VERSION ""

NS_ :

BS_:

BU_: ECU Display VCU SteeringWheel WirelessGateway DATA_COLLECTION_INTEGRAL VEHICLE_LOGGER PDM FanController BMS_Master Competition_Meter FS_Datalogger Chroma LegacyCharger

BO_ 1289 Debug9: 5 ECU
 SG_ LogicState_RR : 24|4@1+ (1,0) [0|15] "" Vector__XXX
 SG_ LogicState_RL : 28|4@1+ (1,0) [0|15] "" Vector__XXX
 SG_ LogicState_FR : 32|4@1+ (1,0) [0|15] "" Vector__XXX
 SG_ LogicState_FL : 36|4@1+ (1,0) [0|15] "" Vector__XXX
 SG_ FR_AMK_bEnable : 20|1@1+ (1,0) [0|1] "" Vector__XXX
 SG_ FL_AMK_bEnable : 21|1@1+ (1,0) [0|1] "" Vector__XXX
 SG_ RR_AMK_bEnable : 22|1@1+ (1,0) [0|1] "" Vector__XXX
 SG_ RL_AMK_bEnable : 23|1@1+ (1,0) [0|1] "" Vector__XXX
 SG_ FR_AMK_bQuitInverterOn : 16|1@1+ (1,0) [0|1] "" Vector__XXX
 SG_ FL_AMK_bQuitInverterOn : 17|1@1+ (1,0) [0|1] "" Vector__XXX
 SG_ RR_AMK_bQuitInverterOn : 18|1@1+ (1,0) [0|1] "" Vector__XXX
 SG_ RL_AMK_bQuitInverterOn : 19|1@1+ (1,0) [0|1] "" Vector__XXX
 SG_ FR_AMK_bQuitDcOn : 12|1@1+ (1,0) [0|1] "" Vector__XXX
 SG_ FL_AMK_bQuitDcOn : 13|1@1+ (1,0) [0|1] "" Vector__XXX
 SG_ RR_AMK_bQuitDcOn : 14|1@1+ (1,0) [0|1] "" Vector__XXX
 SG_ RL_AMK_bQuitDcOn : 15|1@1+ (1,0) [0|1] "" Vector__XXX
 SG_ FR_AMK_bSystemReady : 8|1@1+ (1,0) [0|1] "" Vector__XXX
 SG_ FL_AMK_bSystemReady : 9|1@1+ (1,0) [0|1] "" Vector__XXX
 SG_ RR_AMK_bSystemReady : 10|1@1+ (1,0) [0|1] "" Vector__XXX
 SG_ RL_AMK_bSystemReady : 11|1@1+ (1,0) [0|1] "" Vector__XXX
 SG_ FR_AMK_bError : 0|1@1+ (1,0) [0|1] "" Vector__XXX
 SG_ FL_AMK_bError : 1|1@1+ (1,0) [0|1] "" Vector__XXX
 SG_ RR_AMK_bError : 2|1@1+ (1,0) [0|1] "" Vector__XXX
 SG_ RL_AMK_bError : 3|1@1+ (1,0) [0|1] "" Vector__XXX
 SG_ ModeFlag : 4|4@1- (1,0) [-8|7] "" Vector__XXX

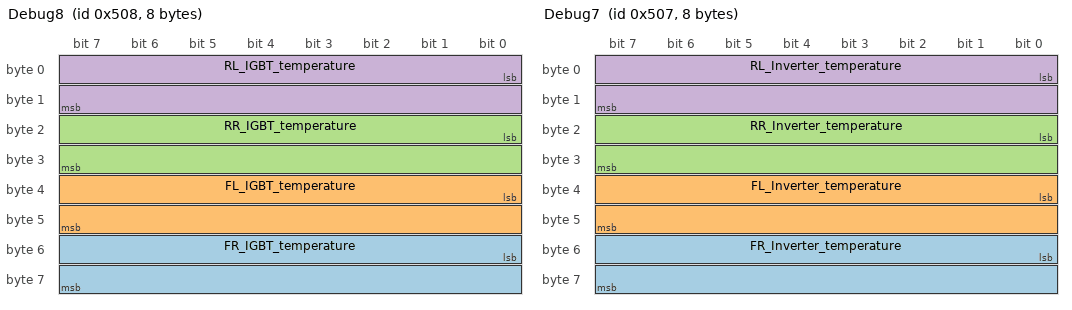
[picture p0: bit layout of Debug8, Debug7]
BO_ 1288 Debug8: 8 ECU
 SG_ FR_IGBT_temperature : 48|16@1- (0.1,0) [-3276.8|3276.7] "degC" Vector__XXX
 SG_ FL_IGBT_temperature : 32|16@1- (0.1,0) [-3276.8|3276.7] "degC" Vector__XXX
 SG_ RR_IGBT_temperature : 16|16@1- (0.1,0) [-3276.8|3276.7] "degC" Vector__XXX
 SG_ RL_IGBT_temperature : 0|16@1- (0.1,0) [-3276.8|3276.7] "degC" Vector__XXX

BO_ 1287 Debug7: 8 ECU
 SG_ FR_Inverter_temperature : 48|16@1- (0.1,0) [-3276.8|3276.7] "degC" Vector__XXX
 SG_ FL_Inverter_temperature : 32|16@1- (0.1,0) [-3276.8|3276.7] "degC" Vector__XXX
 SG_ RR_Inverter_temperature : 16|16@1- (0.1,0) [-3276.8|3276.7] "degC" Vector__XXX
 SG_ RL_Inverter_temperature : 0|16@1- (0.1,0) [-3276.8|3276.7] "degC" Vector__XXX

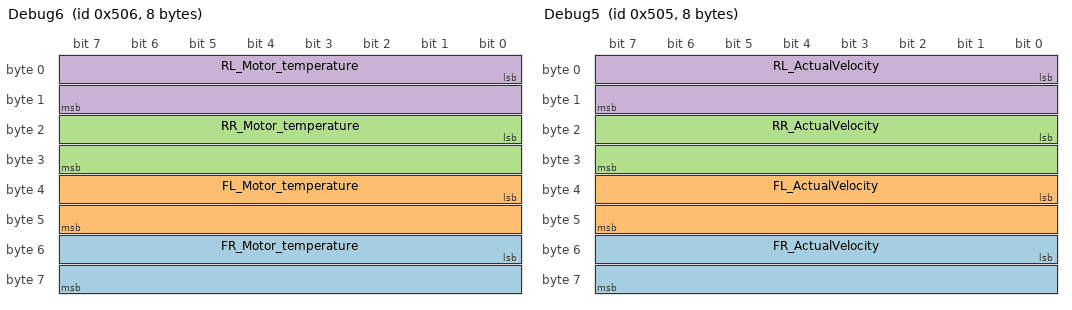
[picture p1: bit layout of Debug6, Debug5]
BO_ 1286 Debug6: 8 ECU
 SG_ FR_Motor_temperature : 48|16@1- (0.1,0) [-3276.8|3276.7] "degC" Vector__XXX
 SG_ FL_Motor_temperature : 32|16@1- (0.1,0) [-3276.8|3276.7] "degC" Vector__XXX
 SG_ RR_Motor_temperature : 16|16@1- (0.1,0) [-3276.8|3276.7] "degC" Vector__XXX
 SG_ RL_Motor_temperature : 0|16@1- (0.1,0) [-3276.8|3276.7] "degC" Vector__XXX

BO_ 1285 Debug5: 8 ECU
 SG_ FR_ActualVelocity : 48|16@1- (1,0) [-32768|32767] "" Vector__XXX
 SG_ FL_ActualVelocity : 32|16@1- (1,0) [-32768|32767] "" Vector__XXX
 SG_ RR_ActualVelocity : 16|16@1- (1,0) [-32768|32767] "" Vector__XXX
 SG_ RL_ActualVelocity : 0|16@1- (1,0) [-32768|32767] "" Vector__XXX

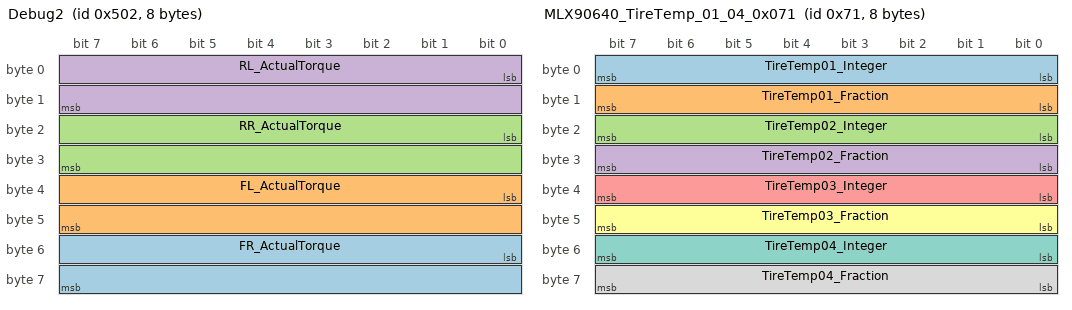
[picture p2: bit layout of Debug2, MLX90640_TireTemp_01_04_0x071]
BO_ 1282 Debug2: 8 ECU
 SG_ FR_ActualTorque : 48|16@1- (1,0) [-32768|32767] "0.1%Mn" Vector__XXX
 SG_ FL_ActualTorque : 32|16@1- (1,0) [-32768|32767] "0.1%Mn" Vector__XXX
 SG_ RR_ActualTorque : 16|16@1- (1,0) [-32768|32767] "0.1%Mn" Vector__XXX
 SG_ RL_ActualTorque : 0|16@1- (1,0) [-32768|32767] "0.1%Mn" Vector__XXX

BO_ 773 DataLogger: 6 ECU
 SG_ OilPressure_Kpa : 32|16@1+ (0.001,0) [0|65.535] "Kpa" Vector__XXX
 SG_ APS_OpenPct : 16|16@1+ (0.1,0) [0|6553.5] "%" Vector__XXX
 SG_ SteeringWheelAngle : 0|16@1- (0.1,0) [-3276.8|3276.7] "deg" Vector__XXX

BO_ 1284 Debug4: 8 ECU
 SG_ Diagnostic_number_4 : 32|32@1+ (1,0) [0|4294967295] "" Vector__XXX
 SG_ Diagnostic_number_3 : 0|32@1+ (1,0) [0|4294967295] "" Vector__XXX

BO_ 1283 Debug3: 8 ECU
 SG_ Diagnostic_number_2 : 32|32@1+ (1,0) [0|4294967295] "" Vector__XXX
 SG_ Diagnostic_number_1 : 0|32@1+ (1,0) [0|4294967295] "" Vector__XXX

BO_ 113 MLX90640_TireTemp_01_04_0x071: 8 DATA_COLLECTION_INTEGRAL
 SG_ TireTemp01_Integer : 0|8@1+ (1,0) [0|255] "degC"  Display,WirelessGateway,VEHICLE_LOGGER
 SG_ TireTemp01_Fraction : 8|8@1+ (0.01,0) [0|0.99] "degC"  Display,WirelessGateway,VEHICLE_LOGGER
 SG_ TireTemp02_Integer : 16|8@1+ (1,0) [0|255] "degC"  Display,WirelessGateway,VEHICLE_LOGGER
 SG_ TireTemp02_Fraction : 24|8@1+ (0.01,0) [0|0.99] "degC"  Display,WirelessGateway,VEHICLE_LOGGER
 SG_ TireTemp03_Integer : 32|8@1+ (1,0) [0|255] "degC"  Display,WirelessGateway,VEHICLE_LOGGER
 SG_ TireTemp03_Fraction : 40|8@1+ (0.01,0) [0|0.99] "degC"  Display,WirelessGateway,VEHICLE_LOGGER
 SG_ TireTemp04_Integer : 48|8@1+ (1,0) [0|255] "degC"  Display,WirelessGateway,VEHICLE_LOGGER
 SG_ TireTemp04_Fraction : 56|8@1+ (0.01,0) [0|0.99] "degC"  Display,WirelessGateway,VEHICLE_LOGGER

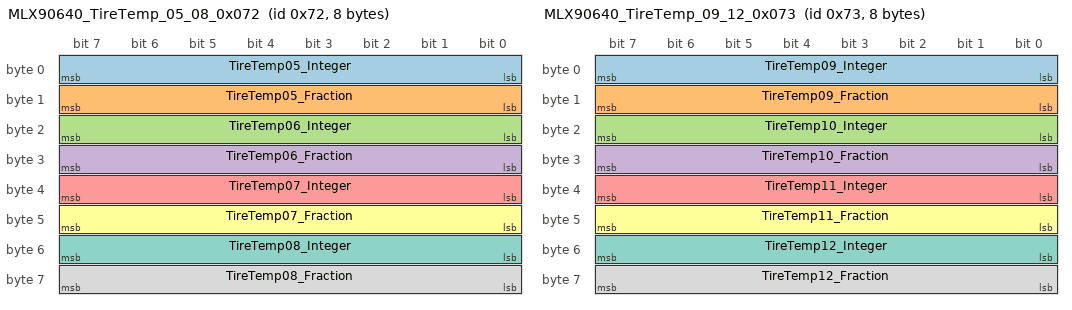
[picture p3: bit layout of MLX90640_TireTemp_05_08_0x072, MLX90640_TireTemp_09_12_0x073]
BO_ 114 MLX90640_TireTemp_05_08_0x072: 8 DATA_COLLECTION_INTEGRAL
 SG_ TireTemp05_Integer : 0|8@1+ (1,0) [0|255] "degC"  Display,WirelessGateway,VEHICLE_LOGGER
 SG_ TireTemp05_Fraction : 8|8@1+ (0.01,0) [0|0.99] "degC"  Display,WirelessGateway,VEHICLE_LOGGER
 SG_ TireTemp06_Integer : 16|8@1+ (1,0) [0|255] "degC"  Display,WirelessGateway,VEHICLE_LOGGER
 SG_ TireTemp06_Fraction : 24|8@1+ (0.01,0) [0|0.99] "degC"  Display,WirelessGateway,VEHICLE_LOGGER
 SG_ TireTemp07_Integer : 32|8@1+ (1,0) [0|255] "degC"  Display,WirelessGateway,VEHICLE_LOGGER
 SG_ TireTemp07_Fraction : 40|8@1+ (0.01,0) [0|0.99] "degC"  Display,WirelessGateway,VEHICLE_LOGGER
 SG_ TireTemp08_Integer : 48|8@1+ (1,0) [0|255] "degC"  Display,WirelessGateway,VEHICLE_LOGGER
 SG_ TireTemp08_Fraction : 56|8@1+ (0.01,0) [0|0.99] "degC"  Display,WirelessGateway,VEHICLE_LOGGER

BO_ 115 MLX90640_TireTemp_09_12_0x073: 8 DATA_COLLECTION_INTEGRAL
 SG_ TireTemp09_Integer : 0|8@1+ (1,0) [0|255] "degC"  Display,WirelessGateway,VEHICLE_LOGGER
 SG_ TireTemp09_Fraction : 8|8@1+ (0.01,0) [0|0.99] "degC"  Display,WirelessGateway,VEHICLE_LOGGER
 SG_ TireTemp10_Integer : 16|8@1+ (1,0) [0|255] "degC"  Display,WirelessGateway,VEHICLE_LOGGER
 SG_ TireTemp10_Fraction : 24|8@1+ (0.01,0) [0|0.99] "degC"  Display,WirelessGateway,VEHICLE_LOGGER
 SG_ TireTemp11_Integer : 32|8@1+ (1,0) [0|255] "degC"  Display,WirelessGateway,VEHICLE_LOGGER
 SG_ TireTemp11_Fraction : 40|8@1+ (0.01,0) [0|0.99] "degC"  Display,WirelessGateway,VEHICLE_LOGGER
 SG_ TireTemp12_Integer : 48|8@1+ (1,0) [0|255] "degC"  Display,WirelessGateway,VEHICLE_LOGGER
 SG_ TireTemp12_Fraction : 56|8@1+ (0.01,0) [0|0.99] "degC"  Display,WirelessGateway,VEHICLE_LOGGER

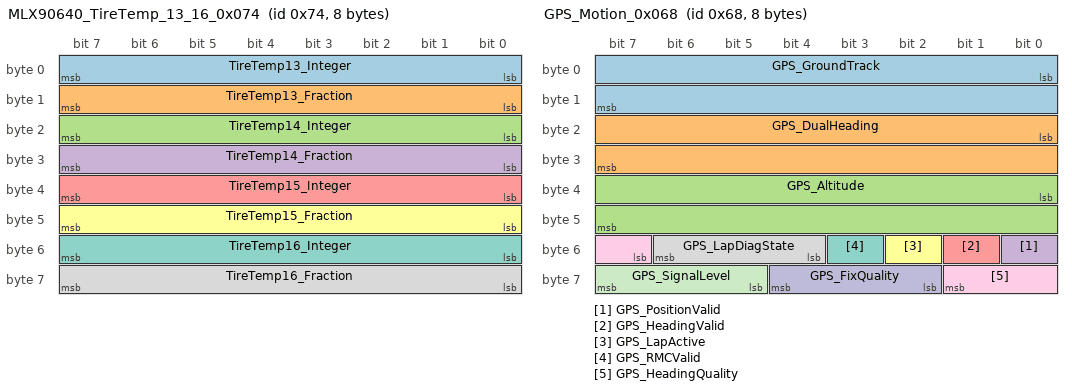
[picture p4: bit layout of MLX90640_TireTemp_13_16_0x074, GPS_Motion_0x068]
BO_ 116 MLX90640_TireTemp_13_16_0x074: 8 DATA_COLLECTION_INTEGRAL
 SG_ TireTemp13_Integer : 0|8@1+ (1,0) [0|255] "degC"  Display,WirelessGateway,VEHICLE_LOGGER
 SG_ TireTemp13_Fraction : 8|8@1+ (0.01,0) [0|0.99] "degC"  Display,WirelessGateway,VEHICLE_LOGGER
 SG_ TireTemp14_Integer : 16|8@1+ (1,0) [0|255] "degC"  Display,WirelessGateway,VEHICLE_LOGGER
 SG_ TireTemp14_Fraction : 24|8@1+ (0.01,0) [0|0.99] "degC"  Display,WirelessGateway,VEHICLE_LOGGER
 SG_ TireTemp15_Integer : 32|8@1+ (1,0) [0|255] "degC"  Display,WirelessGateway,VEHICLE_LOGGER
 SG_ TireTemp15_Fraction : 40|8@1+ (0.01,0) [0|0.99] "degC"  Display,WirelessGateway,VEHICLE_LOGGER
 SG_ TireTemp16_Integer : 48|8@1+ (1,0) [0|255] "degC"  Display,WirelessGateway,VEHICLE_LOGGER
 SG_ TireTemp16_Fraction : 56|8@1+ (0.01,0) [0|0.99] "degC"  Display,WirelessGateway,VEHICLE_LOGGER

BO_ 769 GPS_Speed: 2 Display
 SG_ GroundSpeed : 0|16@1+ (0.1,0) [0|300] "km/h"  ECU,WirelessGateway

BO_ 103 GPS_Position_0x067: 8 Display
 SG_ GPS_Latitude : 0|32@1- (1e-07,0) [-90|90] "deg"  WirelessGateway
 SG_ GPS_Longitude : 32|32@1- (1e-07,0) [-180|180] "deg"  WirelessGateway

BO_ 104 GPS_Motion_0x068: 8 Display
 SG_ GPS_GroundTrack : 0|16@1+ (0.01,0) [0|359.99] "deg"  WirelessGateway
 SG_ GPS_DualHeading : 16|16@1+ (0.01,0) [0|359.99] "deg"  WirelessGateway
 SG_ GPS_Altitude : 32|16@1- (0.1,0) [-3276.8|3276.7] "m"  WirelessGateway
 SG_ GPS_PositionValid : 48|1@1+ (1,0) [0|1] ""  WirelessGateway
 SG_ GPS_HeadingValid : 49|1@1+ (1,0) [0|1] ""  WirelessGateway
 SG_ GPS_LapActive : 50|1@1+ (1,0) [0|1] ""  WirelessGateway
 SG_ GPS_RMCValid : 51|1@1+ (1,0) [0|1] ""  WirelessGateway
 SG_ GPS_LapDiagState : 52|3@1+ (1,0) [0|6] ""  WirelessGateway
 SG_ GPS_HeadingQuality : 55|3@1+ (1,0) [0|7] ""  WirelessGateway
 SG_ GPS_FixQuality : 58|3@1+ (1,0) [0|7] ""  WirelessGateway
 SG_ GPS_SignalLevel : 61|3@1+ (1,0) [0|4] ""  WirelessGateway

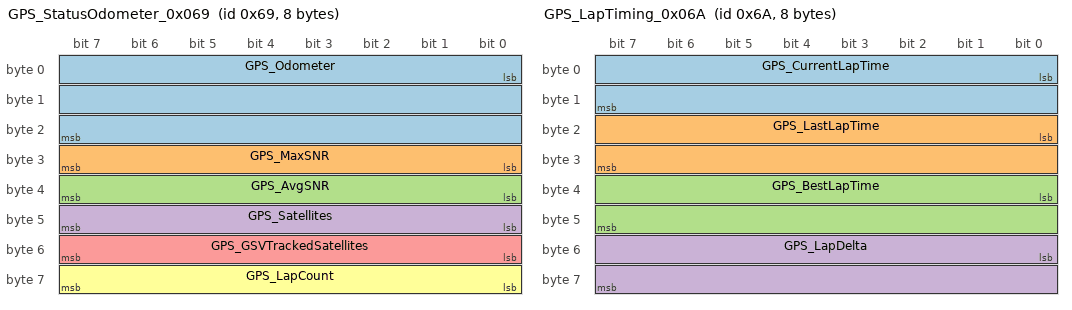
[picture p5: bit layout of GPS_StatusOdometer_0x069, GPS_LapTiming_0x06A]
BO_ 105 GPS_StatusOdometer_0x069: 8 Display
 SG_ GPS_Odometer : 0|24@1+ (0.1,0) [0|1677721.5] "km"  WirelessGateway
 SG_ GPS_MaxSNR : 24|8@1- (1,0) [-128|127] "dB-Hz"  WirelessGateway
 SG_ GPS_AvgSNR : 32|8@1- (1,0) [-128|127] "dB-Hz"  WirelessGateway
 SG_ GPS_Satellites : 40|8@1+ (1,0) [0|255] ""  WirelessGateway
 SG_ GPS_GSVTrackedSatellites : 48|8@1+ (1,0) [0|255] ""  WirelessGateway
 SG_ GPS_LapCount : 56|8@1+ (1,0) [0|255] "lap"  WirelessGateway

BO_ 106 GPS_LapTiming_0x06A: 8 Display
 SG_ GPS_CurrentLapTime : 0|16@1+ (0.01,0) [0|655.35] "s"  WirelessGateway
 SG_ GPS_LastLapTime : 16|16@1+ (0.01,0) [0|655.35] "s"  WirelessGateway
 SG_ GPS_BestLapTime : 32|16@1+ (0.01,0) [0|655.35] "s"  WirelessGateway
 SG_ GPS_LapDelta : 48|16@1- (0.01,0) [-327.68|327.67] "s"  WirelessGateway

BO_ 1792 SlipLevel_0x700: 1 SteeringWheel
 SG_ SlipLevel : 0|8@1+ (1,0) [0|7] ""  VCU,Display

BO_ 1793 RecorderToggle_0x701: 1 SteeringWheel
 SG_ RecorderToggle : 0|1@1+ (1,0) [0|1] ""  VCU,Display

BO_ 1794 ErrorClear_0x702: 1 SteeringWheel
 SG_ ErrorClearActive : 0|1@1+ (1,0) [0|1] ""  VCU,Display

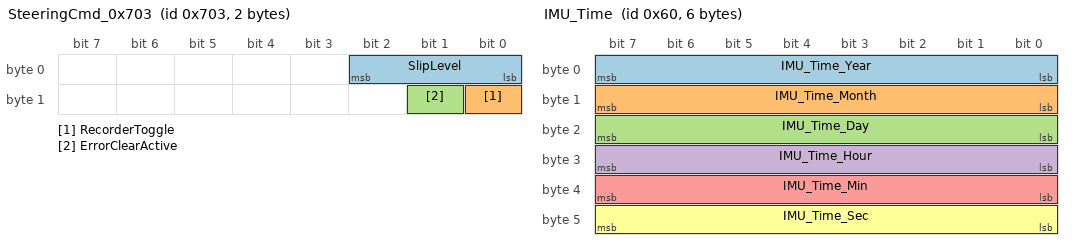
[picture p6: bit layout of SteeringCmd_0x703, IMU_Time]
BO_ 1795 SteeringCmd_0x703: 2 Display
 SG_ SlipLevel : 0|3@1+ (1,0) [0|7] ""  ECU
 SG_ RecorderToggle : 8|1@1+ (1,0) [0|1] ""  ECU
 SG_ ErrorClearActive : 9|1@1+ (1,0) [0|1] ""  ECU

BO_ 1924 DriveMode_0x784: 8 SteeringWheel
 SG_ DriveMode : 0|8@1+ (1,0) [0|3] ""  VCU,Display

BO_ 784 DriveMode_Request: 8 Display
 SG_ DriveModeCode : 0|8@1+ (1,0) [48|51] ""  ECU

BO_ 80 IMU_Raw: 8 Display
 SG_ IMU_Header : 0|8@1+ (1,0) [85|85] "" Vector__XXX
 SG_ IMU_SubType : 8|8@1+ (1,0) [80|84] "" Vector__XXX
 SG_ IMU_RawData : 16|48@1+ (1,0) [0|281474976710655] "" Vector__XXX

BO_ 96 IMU_Time: 6 Display
 SG_ IMU_Time_Year : 0|8@1+ (1,2000) [0|99] "" Vector__XXX
 SG_ IMU_Time_Month : 8|8@1+ (1,0) [1|12] "" Vector__XXX
 SG_ IMU_Time_Day : 16|8@1+ (1,0) [1|31] "" Vector__XXX
 SG_ IMU_Time_Hour : 24|8@1+ (1,0) [0|23] "" Vector__XXX
 SG_ IMU_Time_Min : 32|8@1+ (1,0) [0|59] "" Vector__XXX
 SG_ IMU_Time_Sec : 40|8@1+ (1,0) [0|59] "" Vector__XXX

BO_ 97 IMU_Accel: 6 Display
 SG_ IMU_AccelX : 0|16@1- (0.00048828125,0) [-16|16] "g" Vector__XXX
 SG_ IMU_AccelY : 16|16@1- (0.00048828125,0) [-16|16] "g" Vector__XXX
 SG_ IMU_AccelZ : 32|16@1- (0.00048828125,0) [-16|16] "g" Vector__XXX

BO_ 98 IMU_Gyro: 6 Display
 SG_ IMU_GyroX : 0|16@1- (0.0610352,0) [-2000|2000] "deg/s" Vector__XXX
 SG_ IMU_GyroY : 16|16@1- (0.0610352,0) [-2000|2000] "deg/s" Vector__XXX
 SG_ IMU_GyroZ : 32|16@1- (0.0610352,0) [-2000|2000] "deg/s" Vector__XXX

BO_ 99 IMU_Roll: 2 Display
 SG_ IMU_Angle_Roll : 0|16@1- (0.005493,0) [-180|180] "deg" Vector__XXX

BO_ 100 IMU_Pitch: 2 Display
 SG_ IMU_Angle_Pitch : 0|16@1- (0.005493,0) [-90|90] "deg" Vector__XXX

BO_ 101 IMU_Yaw: 2 Display
 SG_ IMU_Angle_Yaw : 0|16@1- (0.005493,0) [-180|180] "deg" Vector__XXX

BO_ 102 IMU_Magnetic: 6 Display
 SG_ IMU_MagX : 0|16@1- (1,0) [-32768|32767] "" Vector__XXX
 SG_ IMU_MagY : 16|16@1- (1,0) [-32768|32767] "" Vector__XXX
 SG_ IMU_MagZ : 32|16@1- (1,0) [-32768|32767] "" Vector__XXX

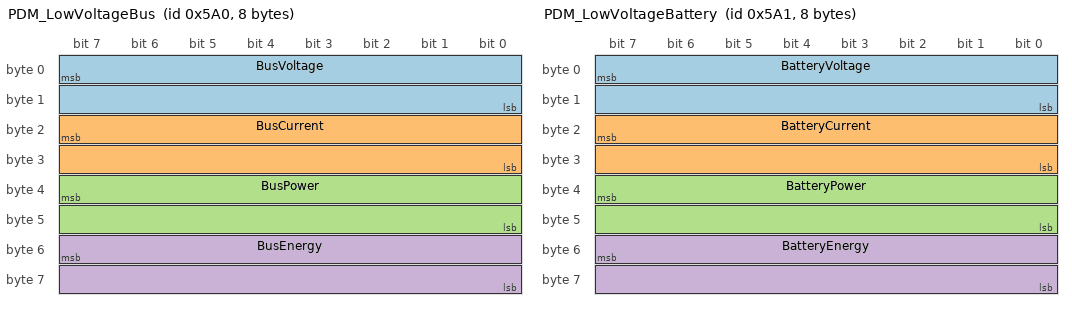
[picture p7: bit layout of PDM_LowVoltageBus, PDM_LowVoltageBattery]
BO_ 1440 PDM_LowVoltageBus: 8 PDM
 SG_ BusVoltage : 7|16@0- (0.001,0) [-32.768|32.767] "V"  ECU
 SG_ BusCurrent : 23|16@0- (0.01,0) [-327.68|327.67] "A"  ECU
 SG_ BusPower : 39|16@0+ (0.1,0) [0|6553.5] "W"  ECU
 SG_ BusEnergy : 55|16@0+ (0.01,0) [0|655.35] "Wh"  ECU

BO_ 1441 PDM_LowVoltageBattery: 8 PDM
 SG_ BatteryVoltage : 7|16@0- (0.001,0) [-32.768|32.767] "V"  ECU
 SG_ BatteryCurrent : 23|16@0- (0.01,0) [-327.68|327.67] "A"  ECU
 SG_ BatteryPower : 39|16@0+ (0.1,0) [0|6553.5] "W"  ECU
 SG_ BatteryEnergy : 55|16@0+ (0.01,0) [0|655.35] "Wh"  ECU

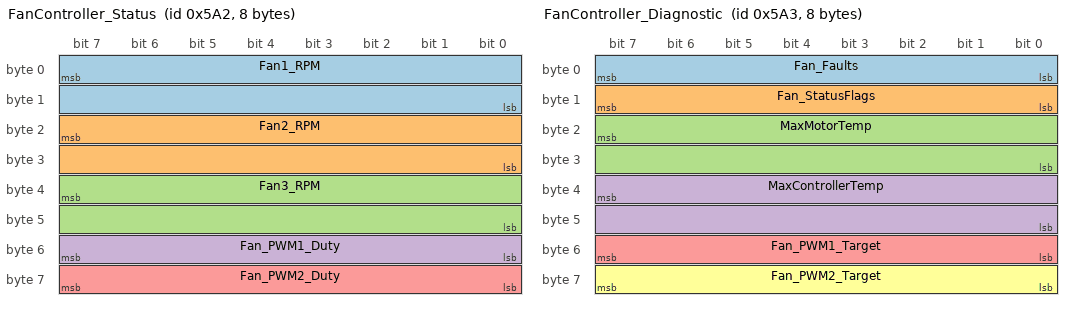
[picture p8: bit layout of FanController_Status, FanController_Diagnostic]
BO_ 1442 FanController_Status: 8 FanController
 SG_ Fan1_RPM : 7|16@0+ (1,0) [0|65535] "rpm"  ECU
 SG_ Fan2_RPM : 23|16@0+ (1,0) [0|65535] "rpm"  ECU
 SG_ Fan3_RPM : 39|16@0+ (1,0) [0|65535] "rpm"  ECU
 SG_ Fan_PWM1_Duty : 55|8@0+ (1,0) [0|100] "%"  ECU
 SG_ Fan_PWM2_Duty : 63|8@0+ (1,0) [0|100] "%"  ECU

BO_ 1443 FanController_Diagnostic: 8 FanController
 SG_ Fan_Faults : 7|8@0+ (1,0) [0|255] ""  ECU
 SG_ Fan_StatusFlags : 15|8@0+ (1,0) [0|255] ""  ECU
 SG_ MaxMotorTemp : 23|16@0- (0.1,0) [-3276.8|3276.7] "degC"  ECU
 SG_ MaxControllerTemp : 39|16@0- (0.1,0) [-3276.8|3276.7] "degC"  ECU
 SG_ Fan_PWM1_Target : 55|8@0+ (1,0) [0|100] "%"  ECU
 SG_ Fan_PWM2_Target : 63|8@0+ (1,0) [0|100] "%"  ECU

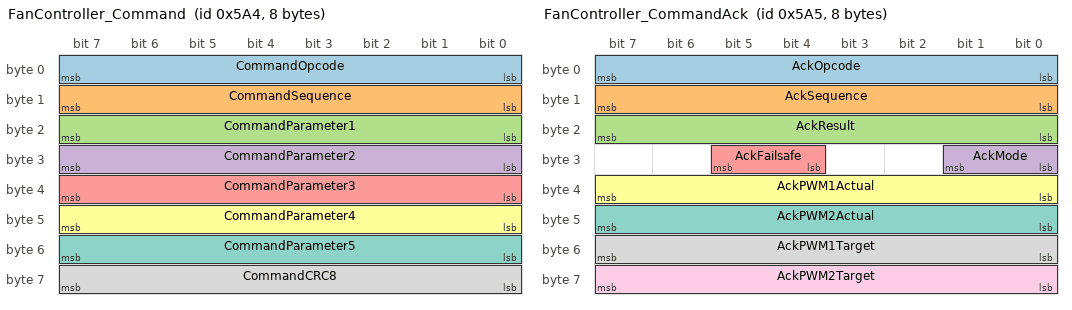
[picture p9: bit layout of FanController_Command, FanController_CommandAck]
BO_ 1444 FanController_Command: 8 ECU
 SG_ CommandOpcode : 0|8@1+ (1,0) [0|255] ""  FanController
 SG_ CommandSequence : 8|8@1+ (1,0) [0|255] ""  FanController
 SG_ CommandParameter1 : 16|8@1+ (1,0) [0|255] ""  FanController
 SG_ CommandParameter2 : 24|8@1+ (1,0) [0|255] ""  FanController
 SG_ CommandParameter3 : 32|8@1+ (1,0) [0|255] ""  FanController
 SG_ CommandParameter4 : 40|8@1+ (1,0) [0|255] ""  FanController
 SG_ CommandParameter5 : 48|8@1+ (1,0) [0|255] ""  FanController
 SG_ CommandCRC8 : 56|8@1+ (1,0) [0|255] ""  FanController

BO_ 1445 FanController_CommandAck: 8 FanController
 SG_ AckOpcode : 0|8@1+ (1,0) [0|255] ""  ECU
 SG_ AckSequence : 8|8@1+ (1,0) [0|255] ""  ECU
 SG_ AckResult : 16|8@1+ (1,0) [0|255] ""  ECU
 SG_ AckMode : 24|2@1+ (1,0) [0|3] ""  ECU
 SG_ AckFailsafe : 28|2@1+ (1,0) [0|3] ""  ECU
 SG_ AckPWM1Actual : 32|8@1+ (1,0) [0|100] "%"  ECU
 SG_ AckPWM2Actual : 40|8@1+ (1,0) [0|100] "%"  ECU
 SG_ AckPWM1Target : 48|8@1+ (1,0) [0|100] "%"  ECU
 SG_ AckPWM2Target : 56|8@1+ (1,0) [0|100] "%"  ECU

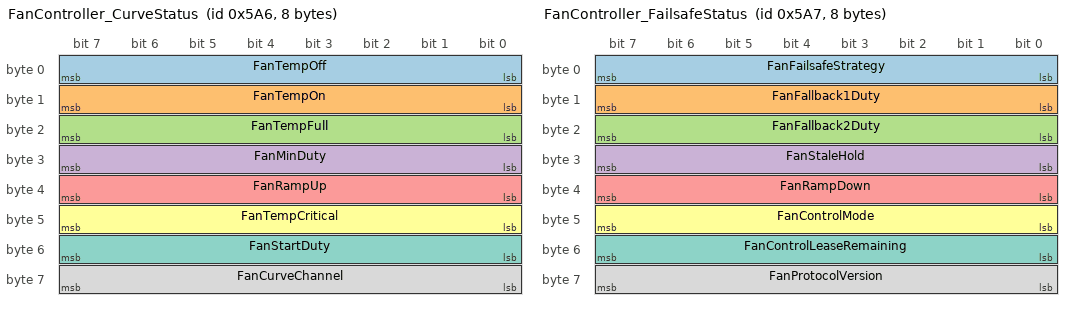
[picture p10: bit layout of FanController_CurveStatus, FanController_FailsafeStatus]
BO_ 1446 FanController_CurveStatus: 8 FanController
 SG_ FanTempOff : 0|8@1+ (1,0) [0|150] "degC"  ECU
 SG_ FanTempOn : 8|8@1+ (1,0) [0|150] "degC"  ECU
 SG_ FanTempFull : 16|8@1+ (1,0) [0|150] "degC"  ECU
 SG_ FanMinDuty : 24|8@1+ (1,0) [0|100] "%"  ECU
 SG_ FanRampUp : 32|8@1+ (1,0) [0|100] "%/s"  ECU
 SG_ FanTempCritical : 40|8@1+ (1,0) [0|150] "degC"  ECU
 SG_ FanStartDuty : 48|8@1+ (1,0) [0|100] "%"  ECU
 SG_ FanCurveChannel : 56|8@1+ (1,0) [1|2] ""  ECU

BO_ 1447 FanController_FailsafeStatus: 8 FanController
 SG_ FanFailsafeStrategy : 0|8@1+ (1,0) [0|2] ""  ECU
 SG_ FanFallback1Duty : 8|8@1+ (1,0) [0|100] "%"  ECU
 SG_ FanFallback2Duty : 16|8@1+ (1,0) [0|100] "%"  ECU
 SG_ FanStaleHold : 24|8@1+ (1,0) [0|30] "s"  ECU
 SG_ FanRampDown : 32|8@1+ (1,0) [0|100] "%/s"  ECU
 SG_ FanControlMode : 40|8@1+ (1,0) [0|2] ""  ECU
 SG_ FanControlLeaseRemaining : 48|8@1+ (1,0) [0|60] "s"  ECU
 SG_ FanProtocolVersion : 56|8@1+ (1,0) [0|255] ""  ECU

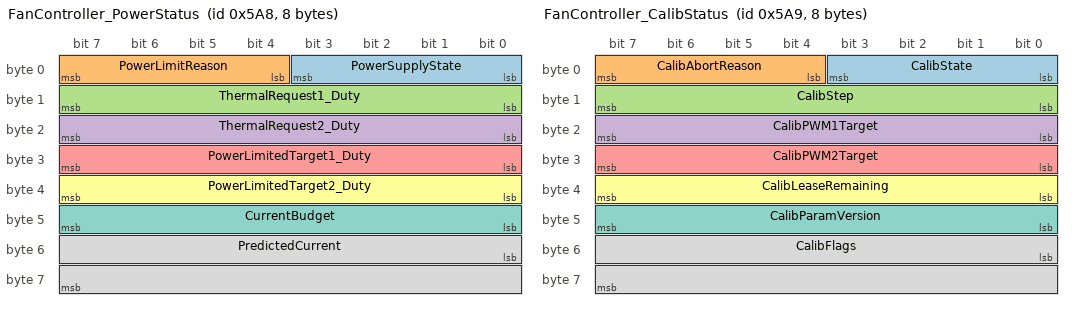
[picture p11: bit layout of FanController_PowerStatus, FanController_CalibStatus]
BO_ 1448 FanController_PowerStatus: 8 FanController
 SG_ PowerSupplyState : 0|4@1+ (1,0) [0|15] ""  ECU
 SG_ PowerLimitReason : 4|4@1+ (1,0) [0|15] ""  ECU
 SG_ ThermalRequest1_Duty : 8|8@1+ (1,0) [0|100] "%"  ECU
 SG_ ThermalRequest2_Duty : 16|8@1+ (1,0) [0|100] "%"  ECU
 SG_ PowerLimitedTarget1_Duty : 24|8@1+ (1,0) [0|100] "%"  ECU
 SG_ PowerLimitedTarget2_Duty : 32|8@1+ (1,0) [0|100] "%"  ECU
 SG_ CurrentBudget : 40|8@1+ (0.1,0) [0|25.5] "A"  ECU
 SG_ PredictedCurrent : 48|16@1+ (0.1,0) [0|6553.5] "A"  ECU

BO_ 1449 FanController_CalibStatus: 8 FanController
 SG_ CalibState : 0|4@1+ (1,0) [0|15] ""  ECU
 SG_ CalibAbortReason : 4|4@1+ (1,0) [0|15] ""  ECU
 SG_ CalibStep : 8|8@1+ (1,0) [0|255] ""  ECU
 SG_ CalibPWM1Target : 16|8@1+ (1,0) [0|100] "%"  ECU
 SG_ CalibPWM2Target : 24|8@1+ (1,0) [0|100] "%"  ECU
 SG_ CalibLeaseRemaining : 32|8@1+ (1,0) [0|255] "s"  ECU
 SG_ CalibParamVersion : 40|8@1+ (1,0) [0|255] ""  ECU
 SG_ CalibFlags : 48|16@1+ (1,0) [0|65535] ""  ECU

BO_ 513 Chroma_VoltageFeedback: 8 Chroma
 SG_ ChromaVoltage : 24|32@1+ (1,0) [0|1000] "V"  BMS_Master

BO_ 514 Chroma_CurrentFeedback: 8 Chroma
 SG_ ChromaCurrent : 24|32@1+ (1,0) [0|1000] "A"  BMS_Master

BO_ 516 Chroma_ProtectionFeedback: 8 Chroma
 SG_ ChromaProtection : 24|32@1+ (1,0) [0|4294967295] ""  BMS_Master

BO_ 517 Chroma_OutputFeedback: 8 Chroma
 SG_ ChromaOutputState : 24|8@1+ (1,0) [0|255] ""  BMS_Master

BO_ 656 Chroma_Command: 6 BMS_Master
 SG_ ChromaCommandCode : 0|8@1+ (1,0) [0|255] ""  Chroma
 SG_ ChromaCommandReserved : 8|8@1+ (1,0) [0|255] ""  Chroma
 SG_ ChromaCommandParameter : 16|32@1+ (1,0) [0|4294967295] ""  Chroma

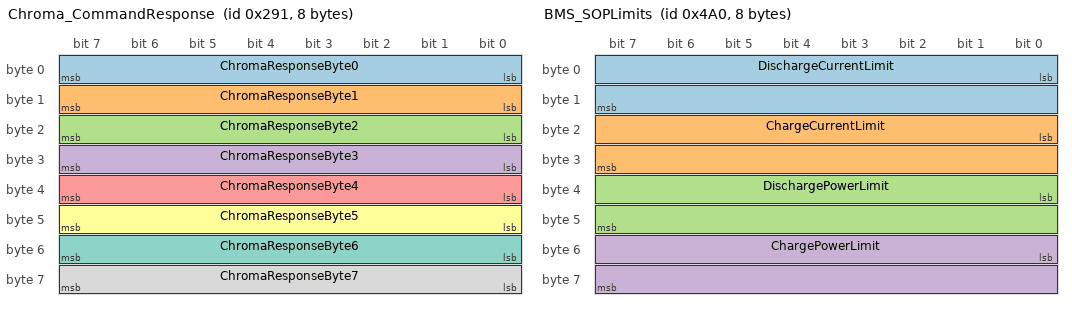
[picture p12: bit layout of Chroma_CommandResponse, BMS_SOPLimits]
BO_ 657 Chroma_CommandResponse: 8 Chroma
 SG_ ChromaResponseByte0 : 0|8@1+ (1,0) [0|255] ""  BMS_Master
 SG_ ChromaResponseByte1 : 8|8@1+ (1,0) [0|255] ""  BMS_Master
 SG_ ChromaResponseByte2 : 16|8@1+ (1,0) [0|255] ""  BMS_Master
 SG_ ChromaResponseByte3 : 24|8@1+ (1,0) [0|255] ""  BMS_Master
 SG_ ChromaResponseByte4 : 32|8@1+ (1,0) [0|255] ""  BMS_Master
 SG_ ChromaResponseByte5 : 40|8@1+ (1,0) [0|255] ""  BMS_Master
 SG_ ChromaResponseByte6 : 48|8@1+ (1,0) [0|255] ""  BMS_Master
 SG_ ChromaResponseByte7 : 56|8@1+ (1,0) [0|255] ""  BMS_Master

BO_ 1184 BMS_SOPLimits: 8 BMS_Master
 SG_ DischargeCurrentLimit : 0|16@1+ (0.1,0) [0|6553.5] "A"  ECU
 SG_ ChargeCurrentLimit : 16|16@1+ (0.1,0) [0|6553.5] "A"  ECU
 SG_ DischargePowerLimit : 32|16@1+ (0.1,0) [0|6553.5] "kW"  ECU
 SG_ ChargePowerLimit : 48|16@1+ (0.1,0) [0|6553.5] "kW"  ECU

BO_ 1187 BMS_SOPStatus: 8 BMS_Master
 SG_ SOPSequence : 0|4@1+ (1,0) [0|15] ""  ECU
 SG_ SOPProtocolVersion : 4|4@1+ (1,0) [0|15] ""  ECU
 SG_ LimitsValid : 8|1@1+ (1,0) [0|1] ""  ECU
 SG_ DriveAllowed : 9|1@1+ (1,0) [0|1] ""  ECU
 SG_ RegenAllowed : 10|1@1+ (1,0) [0|1] ""  ECU
 SG_ OvercurrentLimitZero : 11|1@1+ (1,0) [0|1] ""  ECU
 SG_ BMSFaultHold : 12|1@1+ (1,0) [0|1] ""  ECU
 SG_ SOPAckRequired : 13|1@1+ (1,0) [0|1] ""  ECU
 SG_ LimitsReduced : 14|1@1+ (1,0) [0|1] ""  ECU
 SG_ BatteryState : 16|8@1+ (1,0) [0|255] ""  ECU
 SG_ LimitReason : 24|16@1+ (1,0) [0|65535] ""  ECU
 SG_ InputHealth : 40|8@1+ (1,0) [0|255] ""  ECU
 SG_ InterventionLevel : 48|2@1+ (1,0) [0|3] ""  ECU
 SG_ DischargeOvercurrentZero : 50|1@1+ (1,0) [0|1] ""  ECU
 SG_ ChargeOvercurrentZero : 51|1@1+ (1,0) [0|1] ""  ECU
 SG_ AckMissing : 52|1@1+ (1,0) [0|1] ""  ECU
 SG_ AckFresh : 53|1@1+ (1,0) [0|1] ""  ECU
 SG_ CurrentBelowClearThreshold : 54|1@1+ (1,0) [0|1] ""  ECU
 SG_ SOPCRC8 : 56|8@1+ (1,0) [0|255] ""  ECU

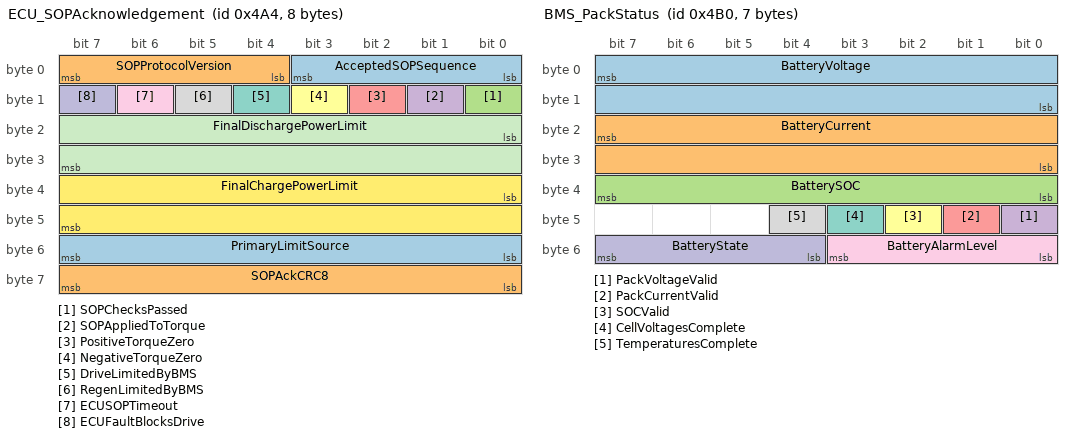
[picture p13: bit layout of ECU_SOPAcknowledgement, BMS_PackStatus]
BO_ 1188 ECU_SOPAcknowledgement: 8 ECU
 SG_ AcceptedSOPSequence : 0|4@1+ (1,0) [0|15] ""  BMS_Master
 SG_ SOPProtocolVersion : 4|4@1+ (1,0) [0|15] ""  BMS_Master
 SG_ SOPChecksPassed : 8|1@1+ (1,0) [0|1] ""  BMS_Master
 SG_ SOPAppliedToTorque : 9|1@1+ (1,0) [0|1] ""  BMS_Master
 SG_ PositiveTorqueZero : 10|1@1+ (1,0) [0|1] ""  BMS_Master
 SG_ NegativeTorqueZero : 11|1@1+ (1,0) [0|1] ""  BMS_Master
 SG_ DriveLimitedByBMS : 12|1@1+ (1,0) [0|1] ""  BMS_Master
 SG_ RegenLimitedByBMS : 13|1@1+ (1,0) [0|1] ""  BMS_Master
 SG_ ECUSOPTimeout : 14|1@1+ (1,0) [0|1] ""  BMS_Master
 SG_ ECUFaultBlocksDrive : 15|1@1+ (1,0) [0|1] ""  BMS_Master
 SG_ FinalDischargePowerLimit : 16|16@1+ (0.1,0) [0|6553.5] "kW"  BMS_Master
 SG_ FinalChargePowerLimit : 32|16@1+ (0.1,0) [0|6553.5] "kW"  BMS_Master
 SG_ PrimaryLimitSource : 48|8@1+ (1,0) [0|255] ""  BMS_Master
 SG_ SOPAckCRC8 : 56|8@1+ (1,0) [0|255] ""  BMS_Master

BO_ 1200 BMS_PackStatus: 7 BMS_Master
 SG_ BatteryVoltage : 7|16@0+ (0.1,0) [0|6553.5] "V"  ECU,VEHICLE_LOGGER,WirelessGateway
 SG_ BatteryCurrent : 23|16@0- (0.1,0) [-3276.8|3276.7] "A"  ECU,VEHICLE_LOGGER,WirelessGateway
 SG_ BatterySOC : 32|8@1+ (1,0) [0|100] "%"  ECU,VEHICLE_LOGGER,WirelessGateway
 SG_ PackVoltageValid : 40|1@1+ (1,0) [0|1] ""  ECU,VEHICLE_LOGGER,WirelessGateway
 SG_ PackCurrentValid : 41|1@1+ (1,0) [0|1] ""  ECU,VEHICLE_LOGGER,WirelessGateway
 SG_ SOCValid : 42|1@1+ (1,0) [0|1] ""  ECU,VEHICLE_LOGGER,WirelessGateway
 SG_ CellVoltagesComplete : 43|1@1+ (1,0) [0|1] ""  ECU,VEHICLE_LOGGER,WirelessGateway
 SG_ TemperaturesComplete : 44|1@1+ (1,0) [0|1] ""  ECU,VEHICLE_LOGGER,WirelessGateway
 SG_ BatteryAlarmLevel : 48|4@1+ (1,0) [0|15] ""  ECU,VEHICLE_LOGGER,WirelessGateway
 SG_ BatteryState : 52|4@1+ (1,0) [0|15] ""  ECU,VEHICLE_LOGGER,WirelessGateway

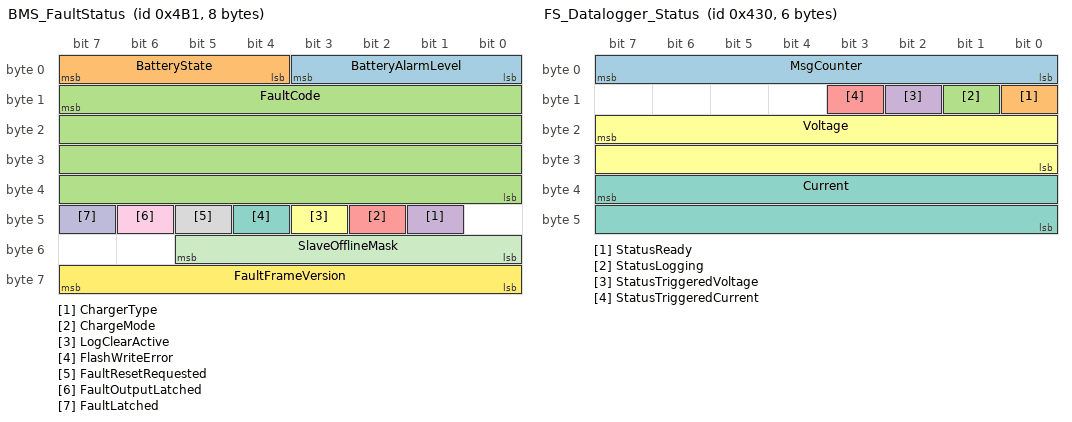
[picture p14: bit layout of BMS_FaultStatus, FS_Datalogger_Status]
BO_ 1201 BMS_FaultStatus: 8 BMS_Master
 SG_ BatteryAlarmLevel : 0|4@1+ (1,0) [0|15] ""  ECU,VEHICLE_LOGGER,WirelessGateway
 SG_ BatteryState : 4|4@1+ (1,0) [0|15] ""  ECU,VEHICLE_LOGGER,WirelessGateway
 SG_ FaultCode : 15|32@0+ (1,0) [0|4294967295] ""  ECU,VEHICLE_LOGGER,WirelessGateway
 SG_ ChargerType : 41|1@1+ (1,0) [0|1] ""  ECU,VEHICLE_LOGGER,WirelessGateway
 SG_ ChargeMode : 42|1@1+ (1,0) [0|1] ""  ECU,VEHICLE_LOGGER,WirelessGateway
 SG_ LogClearActive : 43|1@1+ (1,0) [0|1] ""  ECU,VEHICLE_LOGGER,WirelessGateway
 SG_ FlashWriteError : 44|1@1+ (1,0) [0|1] ""  ECU,VEHICLE_LOGGER,WirelessGateway
 SG_ FaultResetRequested : 45|1@1+ (1,0) [0|1] ""  ECU,VEHICLE_LOGGER,WirelessGateway
 SG_ FaultOutputLatched : 46|1@1+ (1,0) [0|1] ""  ECU,VEHICLE_LOGGER,WirelessGateway
 SG_ FaultLatched : 47|1@1+ (1,0) [0|1] ""  ECU,VEHICLE_LOGGER,WirelessGateway
 SG_ SlaveOfflineMask : 48|6@1+ (1,0) [0|63] ""  ECU,VEHICLE_LOGGER,WirelessGateway
 SG_ FaultFrameVersion : 56|8@1+ (1,0) [0|255] ""  ECU,VEHICLE_LOGGER,WirelessGateway

BO_ 1202 BMS_AlarmLevels: 8 BMS_Master
 SG_ CellOverVoltageLevel : 0|2@1+ (1,0) [0|3] ""  ECU,VEHICLE_LOGGER,WirelessGateway
 SG_ CellUnderVoltageLevel : 2|2@1+ (1,0) [0|3] ""  ECU,VEHICLE_LOGGER,WirelessGateway
 SG_ CellOverTemperatureLevel : 4|2@1+ (1,0) [0|3] ""  ECU,VEHICLE_LOGGER,WirelessGateway
 SG_ CellUnderTemperatureLevel : 6|2@1+ (1,0) [0|3] ""  ECU,VEHICLE_LOGGER,WirelessGateway
 SG_ CellVoltageSenseLevel : 8|2@1+ (1,0) [0|3] ""  ECU,VEHICLE_LOGGER,WirelessGateway
 SG_ TemperatureSenseLevel : 10|2@1+ (1,0) [0|3] ""  ECU,VEHICLE_LOGGER,WirelessGateway
 SG_ CellDeltaVoltageLevel : 12|2@1+ (1,0) [0|3] ""  ECU,VEHICLE_LOGGER,WirelessGateway
 SG_ PackDeltaTemperatureLevel : 14|2@1+ (1,0) [0|3] ""  ECU,VEHICLE_LOGGER,WirelessGateway
 SG_ PackOverVoltageLevel : 16|2@1+ (1,0) [0|3] ""  ECU,VEHICLE_LOGGER,WirelessGateway
 SG_ PackUnderVoltageLevel : 18|2@1+ (1,0) [0|3] ""  ECU,VEHICLE_LOGGER,WirelessGateway
 SG_ AuxiliaryFailureLevel : 20|2@1+ (1,0) [0|3] ""  ECU,VEHICLE_LOGGER,WirelessGateway
 SG_ LowSOCLevel : 22|2@1+ (1,0) [0|3] ""  ECU,VEHICLE_LOGGER,WirelessGateway
 SG_ ChargeSustainedOvercurrentLevel : 24|2@1+ (1,0) [0|3] ""  ECU,VEHICLE_LOGGER,WirelessGateway
 SG_ DischargeSustainedOvercurrentLev : 26|2@1+ (1,0) [0|3] ""  ECU,VEHICLE_LOGGER,WirelessGateway
 SG_ ChargeInstantOvercurrentLevel : 28|2@1+ (1,0) [0|3] ""  ECU,VEHICLE_LOGGER,WirelessGateway
 SG_ DischargeInstantOvercurrentLevel : 30|2@1+ (1,0) [0|3] ""  ECU,VEHICLE_LOGGER,WirelessGateway
 SG_ SlaveOfflineLevel : 32|2@1+ (1,0) [0|3] ""  ECU,VEHICLE_LOGGER,WirelessGateway
 SG_ PrechargeFailureLevel : 34|2@1+ (1,0) [0|3] ""  ECU,VEHICLE_LOGGER,WirelessGateway
 SG_ CriticalControlFailureLevel : 36|2@1+ (1,0) [0|3] ""  ECU,VEHICLE_LOGGER,WirelessGateway
 SG_ PackVoltageMismatchLevel : 38|2@1+ (1,0) [0|3] ""  ECU,VEHICLE_LOGGER,WirelessGateway
 SG_ CurrentSensorFailureLevel : 40|2@1+ (1,0) [0|3] ""  ECU,VEHICLE_LOGGER,WirelessGateway
 SG_ CANRuntimeFailureLevel : 42|2@1+ (1,0) [0|3] ""  ECU,VEHICLE_LOGGER,WirelessGateway
 SG_ ReservedAlarm22Level : 44|2@1+ (1,0) [0|3] ""  ECU,VEHICLE_LOGGER,WirelessGateway
 SG_ ChromaTelemetryLossLevel : 46|2@1+ (1,0) [0|3] ""  ECU,VEHICLE_LOGGER,WirelessGateway
 SG_ ChromaCommandFailureLevel : 48|2@1+ (1,0) [0|3] ""  ECU,VEHICLE_LOGGER,WirelessGateway
 SG_ Slave1OfflineLevel : 50|2@1+ (1,0) [0|3] ""  ECU,VEHICLE_LOGGER,WirelessGateway
 SG_ Slave2OfflineLevel : 52|2@1+ (1,0) [0|3] ""  ECU,VEHICLE_LOGGER,WirelessGateway
 SG_ Slave3OfflineLevel : 54|2@1+ (1,0) [0|3] ""  ECU,VEHICLE_LOGGER,WirelessGateway
 SG_ Slave4OfflineLevel : 56|2@1+ (1,0) [0|3] ""  ECU,VEHICLE_LOGGER,WirelessGateway
 SG_ Slave5OfflineLevel : 58|2@1+ (1,0) [0|3] ""  ECU,VEHICLE_LOGGER,WirelessGateway
 SG_ Slave6OfflineLevel : 60|2@1+ (1,0) [0|3] ""  ECU,VEHICLE_LOGGER,WirelessGateway
 SG_ IVTVoltageLossLevel : 62|2@1+ (1,0) [0|3] ""  ECU,VEHICLE_LOGGER,WirelessGateway

BO_ 1072 FS_Datalogger_Status: 6 FS_Datalogger
 SG_ MsgCounter : 0|8@1+ (1,0) [0|255] ""  VEHICLE_LOGGER,WirelessGateway
 SG_ StatusReady : 8|1@1+ (1,0) [0|1] ""  VEHICLE_LOGGER,WirelessGateway
 SG_ StatusLogging : 9|1@1+ (1,0) [0|1] ""  VEHICLE_LOGGER,WirelessGateway
 SG_ StatusTriggeredVoltage : 10|1@1+ (1,0) [0|1] ""  VEHICLE_LOGGER,WirelessGateway
 SG_ StatusTriggeredCurrent : 11|1@1+ (1,0) [0|1] ""  VEHICLE_LOGGER,WirelessGateway
 SG_ Voltage : 23|16@0+ (16,0) [0|1048560] "mV"  VEHICLE_LOGGER,WirelessGateway
 SG_ Current : 39|16@0+ (64,0) [0|4194240] "mA"  VEHICLE_LOGGER,WirelessGateway

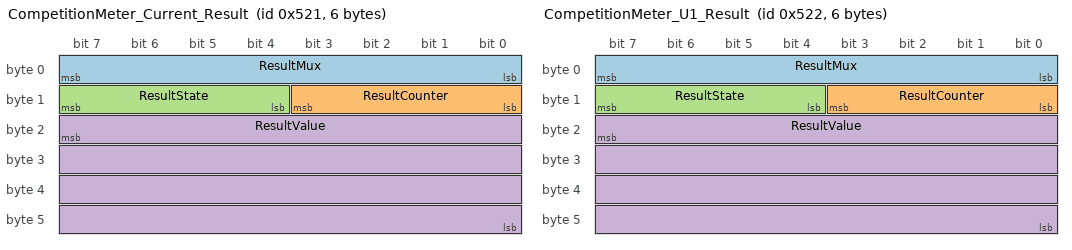
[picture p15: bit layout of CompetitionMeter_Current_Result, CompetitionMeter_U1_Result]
BO_ 1313 CompetitionMeter_Current_Result: 6 Competition_Meter
 SG_ ResultMux : 0|8@1+ (1,0) [0|255] ""  VEHICLE_LOGGER,WirelessGateway
 SG_ ResultCounter : 8|4@1+ (1,0) [0|15] ""  VEHICLE_LOGGER,WirelessGateway
 SG_ ResultState : 12|4@1+ (1,0) [0|15] ""  VEHICLE_LOGGER,WirelessGateway
 SG_ ResultValue : 23|32@0- (1,0) [-2147483648|2147483647] "mA"  VEHICLE_LOGGER,WirelessGateway

BO_ 1314 CompetitionMeter_U1_Result: 6 Competition_Meter
 SG_ ResultMux : 0|8@1+ (1,0) [0|255] ""  VEHICLE_LOGGER,WirelessGateway
 SG_ ResultCounter : 8|4@1+ (1,0) [0|15] ""  VEHICLE_LOGGER,WirelessGateway
 SG_ ResultState : 12|4@1+ (1,0) [0|15] ""  VEHICLE_LOGGER,WirelessGateway
 SG_ ResultValue : 23|32@0- (1,0) [-2147483648|2147483647] "mV"  VEHICLE_LOGGER,WirelessGateway

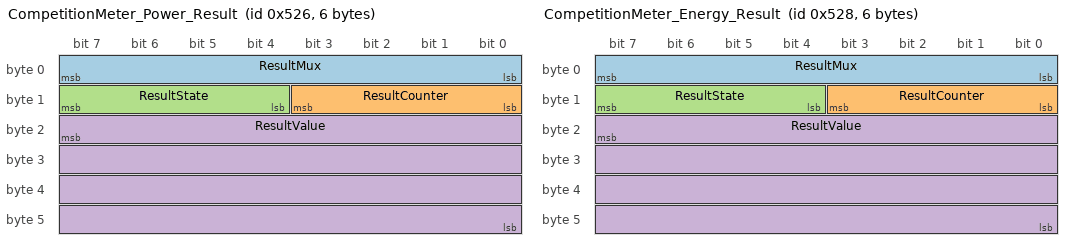
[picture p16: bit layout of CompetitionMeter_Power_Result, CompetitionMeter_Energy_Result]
BO_ 1318 CompetitionMeter_Power_Result: 6 Competition_Meter
 SG_ ResultMux : 0|8@1+ (1,0) [0|255] ""  VEHICLE_LOGGER,WirelessGateway
 SG_ ResultCounter : 8|4@1+ (1,0) [0|15] ""  VEHICLE_LOGGER,WirelessGateway
 SG_ ResultState : 12|4@1+ (1,0) [0|15] ""  VEHICLE_LOGGER,WirelessGateway
 SG_ ResultValue : 23|32@0- (1,0) [-2147483648|2147483647] "W"  VEHICLE_LOGGER,WirelessGateway

BO_ 1320 CompetitionMeter_Energy_Result: 6 Competition_Meter
 SG_ ResultMux : 0|8@1+ (1,0) [0|255] ""  VEHICLE_LOGGER,WirelessGateway
 SG_ ResultCounter : 8|4@1+ (1,0) [0|15] ""  VEHICLE_LOGGER,WirelessGateway
 SG_ ResultState : 12|4@1+ (1,0) [0|15] ""  VEHICLE_LOGGER,WirelessGateway
 SG_ ResultValue : 23|32@0- (1,0) [-2147483648|2147483647] "Wh"  VEHICLE_LOGGER,WirelessGateway

BO_ 2550588916 LegacyCharger_Command: 5 BMS_Master
 SG_ LegacyRequestVoltage : 7|16@0+ (0.1,0) [0|6553.5] "V"  LegacyCharger
 SG_ LegacyRequestCurrent : 23|16@0+ (0.1,0) [0|6553.5] "A"  LegacyCharger
 SG_ LegacyControl : 32|8@1+ (1,0) [0|255] ""  LegacyCharger

BO_ 2566869221 LegacyCharger_Feedback: 8 LegacyCharger
 SG_ LegacyFeedbackVoltage : 7|16@0+ (0.1,0) [0|6553.5] "V"  BMS_Master
 SG_ LegacyFeedbackCurrent : 23|16@0+ (0.1,0) [0|6553.5] "A"  BMS_Master
 SG_ LegacyStatus : 32|8@1+ (1,0) [0|255] ""  BMS_Master

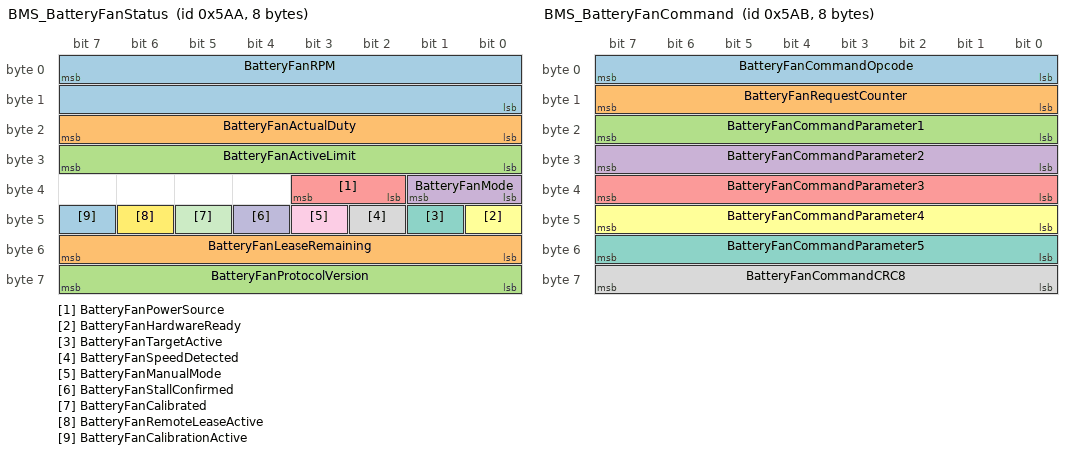
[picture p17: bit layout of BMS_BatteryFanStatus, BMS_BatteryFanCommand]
BO_ 1450 BMS_BatteryFanStatus: 8 BMS_Master
 SG_ BatteryFanRPM : 7|16@0+ (1,0) [0|65535] "rpm"  ECU
 SG_ BatteryFanActualDuty : 16|8@1+ (1,0) [0|100] "%"  ECU
 SG_ BatteryFanActiveLimit : 24|8@1+ (1,0) [0|100] "%"  ECU
 SG_ BatteryFanMode : 32|2@1+ (1,0) [0|2] ""  ECU
 SG_ BatteryFanPowerSource : 34|2@1+ (1,0) [0|2] ""  ECU
 SG_ BatteryFanHardwareReady : 40|1@1+ (1,0) [0|1] ""  ECU
 SG_ BatteryFanTargetActive : 41|1@1+ (1,0) [0|1] ""  ECU
 SG_ BatteryFanSpeedDetected : 42|1@1+ (1,0) [0|1] ""  ECU
 SG_ BatteryFanManualMode : 43|1@1+ (1,0) [0|1] ""  ECU
 SG_ BatteryFanStallConfirmed : 44|1@1+ (1,0) [0|1] ""  ECU
 SG_ BatteryFanCalibrated : 45|1@1+ (1,0) [0|1] ""  ECU
 SG_ BatteryFanRemoteLeaseActive : 46|1@1+ (1,0) [0|1] ""  ECU
 SG_ BatteryFanCalibrationActive : 47|1@1+ (1,0) [0|1] ""  ECU
 SG_ BatteryFanLeaseRemaining : 48|8@1+ (1,0) [0|60] "s"  ECU
 SG_ BatteryFanProtocolVersion : 56|8@1+ (1,0) [0|255] ""  ECU

BO_ 1451 BMS_BatteryFanCommand: 8 ECU
 SG_ BatteryFanCommandOpcode : 0|8@1+ (1,0) [0|255] ""  BMS_Master
 SG_ BatteryFanRequestCounter : 8|8@1+ (1,0) [0|255] ""  BMS_Master
 SG_ BatteryFanCommandParameter1 : 16|8@1+ (1,0) [0|255] ""  BMS_Master
 SG_ BatteryFanCommandParameter2 : 24|8@1+ (1,0) [0|255] ""  BMS_Master
 SG_ BatteryFanCommandParameter3 : 32|8@1+ (1,0) [0|255] ""  BMS_Master
 SG_ BatteryFanCommandParameter4 : 40|8@1+ (1,0) [0|255] ""  BMS_Master
 SG_ BatteryFanCommandParameter5 : 48|8@1+ (1,0) [0|255] ""  BMS_Master
 SG_ BatteryFanCommandCRC8 : 56|8@1+ (1,0) [0|255] ""  BMS_Master

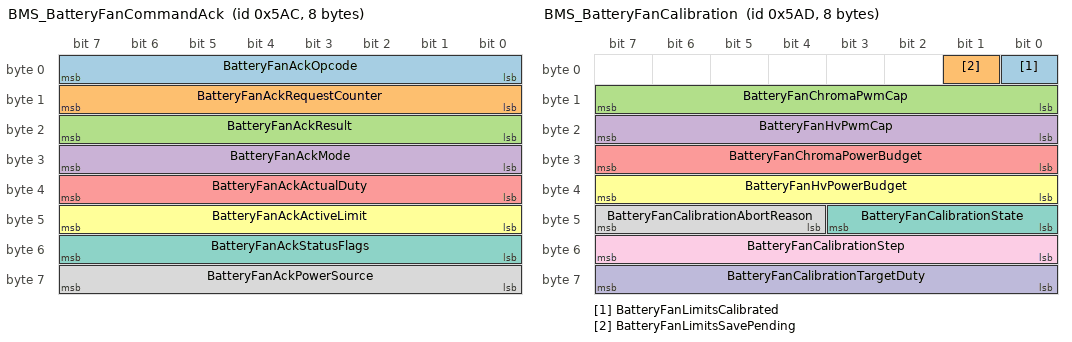
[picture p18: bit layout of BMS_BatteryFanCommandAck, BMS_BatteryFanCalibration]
BO_ 1452 BMS_BatteryFanCommandAck: 8 BMS_Master
 SG_ BatteryFanAckOpcode : 0|8@1+ (1,0) [0|255] ""  ECU
 SG_ BatteryFanAckRequestCounter : 8|8@1+ (1,0) [0|255] ""  ECU
 SG_ BatteryFanAckResult : 16|8@1+ (1,0) [0|7] ""  ECU
 SG_ BatteryFanAckMode : 24|8@1+ (1,0) [0|2] ""  ECU
 SG_ BatteryFanAckActualDuty : 32|8@1+ (1,0) [0|100] "%"  ECU
 SG_ BatteryFanAckActiveLimit : 40|8@1+ (1,0) [0|100] "%"  ECU
 SG_ BatteryFanAckStatusFlags : 48|8@1+ (1,0) [0|255] ""  ECU
 SG_ BatteryFanAckPowerSource : 56|8@1+ (1,0) [0|2] ""  ECU

BO_ 1453 BMS_BatteryFanCalibration: 8 BMS_Master
 SG_ BatteryFanLimitsCalibrated : 0|1@1+ (1,0) [0|1] ""  ECU
 SG_ BatteryFanLimitsSavePending : 1|1@1+ (1,0) [0|1] ""  ECU
 SG_ BatteryFanChromaPwmCap : 8|8@1+ (1,0) [0|100] "%"  ECU
 SG_ BatteryFanHvPwmCap : 16|8@1+ (1,0) [0|100] "%"  ECU
 SG_ BatteryFanChromaPowerBudget : 24|8@1+ (1,0) [0|255] "W"  ECU
 SG_ BatteryFanHvPowerBudget : 32|8@1+ (1,0) [0|255] "W"  ECU
 SG_ BatteryFanCalibrationState : 40|4@1+ (1,0) [0|3] ""  ECU
 SG_ BatteryFanCalibrationAbortReason : 44|4@1+ (1,0) [0|6] ""  ECU
 SG_ BatteryFanCalibrationStep : 48|8@1+ (1,0) [0|255] ""  ECU
 SG_ BatteryFanCalibrationTargetDuty : 56|8@1+ (1,0) [0|100] "%"  ECU

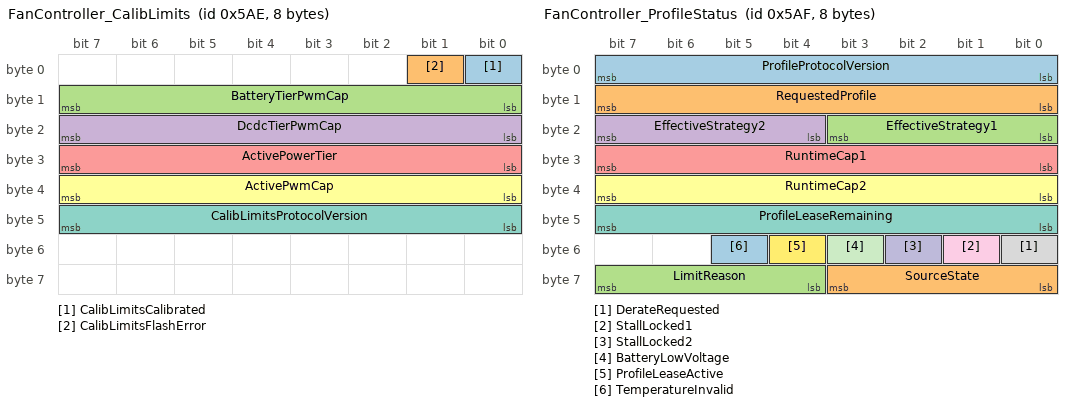
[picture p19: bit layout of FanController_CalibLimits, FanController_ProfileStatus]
BO_ 1454 FanController_CalibLimits: 8 FanController
 SG_ CalibLimitsCalibrated : 0|1@1+ (1,0) [0|1] ""  ECU
 SG_ CalibLimitsFlashError : 1|1@1+ (1,0) [0|1] ""  ECU
 SG_ BatteryTierPwmCap : 8|8@1+ (1,0) [0|100] "%"  ECU
 SG_ DcdcTierPwmCap : 16|8@1+ (1,0) [0|100] "%"  ECU
 SG_ ActivePowerTier : 24|8@1+ (1,0) [0|1] ""  ECU
 SG_ ActivePwmCap : 32|8@1+ (1,0) [0|100] "%"  ECU
 SG_ CalibLimitsProtocolVersion : 40|8@1+ (1,0) [0|255] ""  ECU

BO_ 1455 FanController_ProfileStatus: 8 FanController
 SG_ ProfileProtocolVersion : 0|8@1+ (1,0) [0|4] ""  ECU
 SG_ RequestedProfile : 8|8@1+ (1,0) [0|2] ""  ECU
 SG_ EffectiveStrategy1 : 16|4@1+ (1,0) [0|9] ""  ECU
 SG_ EffectiveStrategy2 : 20|4@1+ (1,0) [0|9] ""  ECU
 SG_ RuntimeCap1 : 24|8@1+ (1,0) [0|100] "%"  ECU
 SG_ RuntimeCap2 : 32|8@1+ (1,0) [0|100] "%"  ECU
 SG_ ProfileLeaseRemaining : 40|8@1+ (1,0) [0|60] "s"  ECU
 SG_ DerateRequested : 48|1@1+ (1,0) [0|1] ""  ECU
 SG_ StallLocked1 : 49|1@1+ (1,0) [0|1] ""  ECU
 SG_ StallLocked2 : 50|1@1+ (1,0) [0|1] ""  ECU
 SG_ BatteryLowVoltage : 51|1@1+ (1,0) [0|1] ""  ECU
 SG_ ProfileLeaseActive : 52|1@1+ (1,0) [0|1] ""  ECU
 SG_ TemperatureInvalid : 53|1@1+ (1,0) [0|1] ""  ECU
 SG_ SourceState : 56|4@1+ (1,0) [0|5] ""  ECU
 SG_ LimitReason : 60|4@1+ (1,0) [0|8] ""  ECU

BO_ 774 BrakePedal_0x306: 8 ECU
 SG_ BrakePedalPct : 0|16@1+ (0.1,0.0) [0|100] "%"  Display
 SG_ BrakePedalSwtSts : 16|1@1+ (1,0) [0|1] ""  Display

CM_ SG_ 1289 FR_AMK_bEnable "Front-right motor enable flag.";
CM_ SG_ 1288 FR_IGBT_temperature "Front-right IGBT temperature in degrees Celsius.";
CM_ SG_ 1287 FR_Inverter_temperature "Front-right inverter temperature in degrees Celsius.";
CM_ SG_ 1286 FR_Motor_temperature "Front-right motor temperature in degrees Celsius.";
CM_ SG_ 1282 FR_ActualTorque "Front-right actual motor torque.";
CM_ SG_ 773 OilPressure_Kpa "Oil pressure signal in kPa.";
CM_ SG_ 773 APS_OpenPct "Accelerator pedal opening percentage.";
CM_ SG_ 773 SteeringWheelAngle "Steering-wheel angle in degrees.";
CM_ BO_ 113 "MLX90640 right-front tire-temperature cells 1..4, standard CAN ID 0x071, DLC=8. R0..R3 map directly to cells 1..4 in payload order, from RF rightmost/outside to RF leftmost/inside. Bytes 0/2/4/6 are unsigned integer degC; bytes 1/3/5/7 are unsigned hundredths 0..99. Full temperature = Integer + Fraction.";
CM_ BO_ 114 "MLX90640 left-front tire-temperature cells 5..8, standard CAN ID 0x072, DLC=8. R0..R3 map directly to cells 5..8 in payload order, from LF rightmost/inside to LF leftmost/outside. Bytes 0/2/4/6 are unsigned integer degC; bytes 1/3/5/7 are unsigned hundredths 0..99. Full temperature = Integer + Fraction.";
CM_ BO_ 115 "MLX90640 left-rear tire-temperature cells 9..12, standard CAN ID 0x073, DLC=8. R0..R3 map directly to cells 9..12 in payload order, from LR leftmost/outside to LR rightmost/inside. Bytes 0/2/4/6 are unsigned integer degC; bytes 1/3/5/7 are unsigned hundredths 0..99. Full temperature = Integer + Fraction.";
CM_ BO_ 116 "MLX90640 right-rear tire-temperature cells 13..16, standard CAN ID 0x074, DLC=8. R0..R3 map directly to cells 13..16 in payload order, from RR leftmost/inside to RR rightmost/outside. Bytes 0/2/4/6 are unsigned integer degC; bytes 1/3/5/7 are unsigned hundredths 0..99. Full temperature = Integer + Fraction.";
CM_ BO_ 769 "Legacy-compatible GPS ground speed, standard CAN ID 0x301, DLC=2, Display->ECU/WirelessGateway, periodic 50 ms. Source is the latest NMEA RMC speed configured at 20 Hz; invalid RMC status or no RMC update for more than 500 ms transmits zero. The DLC remains 2 to avoid breaking the existing ECU receiver; additional GPS data use IDs 0x067 through 0x06A.";
CM_ SG_ 769 GroundSpeed "Bits 0..15, Intel little-endian, unsigned. RMC speed is parsed in knots, converted to 0.01 km/h internally, rounded to 0.1 km/h for CAN, then clamped to 0..300 km/h. Raw value = physical km/h / 0.1.";
CM_ BO_ 103 "GPS position snapshot, standard CAN ID 0x067, DLC=8, Display->WirelessGateway, periodic 50 ms. Latitude and longitude come from the latest valid 20 Hz RMC sentence and are encoded as signed 1e-7 degree integers.";
CM_ BO_ 104 "GPS motion, validity and compact quality snapshot, standard CAN ID 0x068, DLC=8, Display->WirelessGateway, periodic 50 ms. Ground track comes from RMC; dual-antenna heading is the most recent HPR value and its validity bit expires after 1.5 s. HPR is currently configured at 5 Hz. Signal level is the same 0..4 value used by the display bars.";
CM_ SG_ 104 GPS_LapDiagState "The same diagnostic state that drives the display lap indicator: 0=Inactive, 1=WaitArm, 2=Armed, 3=Approaching, 4=GateMiss, 5=ReversePass, 6=Crossed.";
CM_ SG_ 104 GPS_RMCValid "1 means a valid-status RMC sentence has been received within the 500 ms freshness window; when 0, position/track fields may contain the last received values and GroundSpeed is transmitted as zero.";
CM_ SG_ 104 GPS_HeadingValid "1 means the dual-antenna HPR quality is accepted and the most recent HPR sentence is not older than 1.5 s.";
CM_ BO_ 105 "GPS reception status and persistent odometer snapshot, standard CAN ID 0x069, DLC=8, Display->WirelessGateway, periodic 500 ms, and immediately when GPS_LapCount changes. Odometer resolution is 0.1 km. Max/average SNR and tracked-satellite count come from the latest completed GSV window.";
CM_ BO_ 106 "GPS-derived lap timing snapshot, standard CAN ID 0x06A, DLC=8, Display->WirelessGateway, periodic 200 ms, and immediately when GPS_LapCount changes. Times use centiseconds. Unsigned lap times saturate at 655.35 s and signed delta saturates at -327.68..327.67 s.";
CM_ BO_ 1792 "Steering wheel slip-level packet, standard CAN ID 0x700, DLC=1. Byte0 = SlipLevel 0..7; Display re-packs it into 0x703 for the ECU.";
CM_ SG_ 1792 SlipLevel "PA1 ADC potentiometer quantized to eight levels: 0..7.";
CM_ BO_ 1793 "Steering wheel recorder-toggle packet, standard CAN ID 0x701, DLC=1. Bit0 = one-shot recorder toggle; Display merges it into 0x703.";
CM_ SG_ 1793 RecorderToggle "PB12: 0=Idle, 1=ToggleRecorderCmd. Display acts only on the rising edge. Pulse duration and sender trigger require SteeringWheel confirmation.";
CM_ BO_ 1794 "Steering wheel error-clear packet, standard CAN ID 0x702, DLC=1. Bit0 = one-shot error clear; Display merges it into 0x703.";
CM_ SG_ 1794 ErrorClearActive "PB13: 0=Idle, 1=ErrorClear. Display acts only on the rising edge. Pulse duration and sender trigger require SteeringWheel confirmation.";
CM_ BO_ 1795 "Display->ECU steering command, standard CAN ID 0x703, DLC=2. Merged from 0x700/0x701/0x702: byte0 SlipLevel 0..7, byte1 bit0 RecorderToggle, byte1 bit1 ErrorClearActive.";
CM_ BO_ 1924 "Steering wheel redundant drive-mode packet, standard CAN ID 0x784, DLC=8. Sender trigger and redundancy policy require SteeringWheel confirmation.";
CM_ SG_ 1924 DriveMode "Rotary switch S1-S4: 0=S1/S, 1=S2/Q, 2=S3/C, 3=S4/E, 255=Invalid.";
CM_ SG_ 784 DriveModeCode "Drive mode request: 48=S, 49=Q, 50=C, 51=E, Display->ECU";
CM_ SG_ 80 IMU_RawData "Payload selected by IMU_SubType; see decoded packets 0x060 through 0x066.";
CM_ SG_ 80 IMU_SubType "Packet type: 0x50=time, 0x51=acceleration, 0x52=angular velocity, 0x53=angle, 0x54=magnetic field.";
CM_ SG_ 80 IMU_Header "Fixed frame header 0x55.";
CM_ SG_ 96 IMU_Time_Year "Year offset from 2000, decoded from packet 0x050 with SubType 0x50.";
CM_ SG_ 97 IMU_AccelX "X-axis acceleration in g, decoded from packet 0x050 with SubType 0x51.";
CM_ SG_ 98 IMU_GyroX "X-axis angular velocity in deg/s, decoded from packet 0x050 with SubType 0x52.";
CM_ SG_ 99 IMU_Angle_Roll "Roll angle in degrees, decoded from packet 0x050 with SubType 0x53 and SubCmd 1.";
CM_ SG_ 100 IMU_Angle_Pitch "Pitch angle in degrees, decoded from packet 0x050 with SubType 0x53 and SubCmd 2.";
CM_ SG_ 101 IMU_Angle_Yaw "Yaw angle in degrees, decoded from packet 0x050 with SubType 0x53 and SubCmd 3.";
CM_ SG_ 102 IMU_MagX "Raw X-axis magnetic-field value, decoded from packet 0x050 with SubType 0x54.";
CM_ BO_ 1440 "Low-voltage bus status. All four fields at their invalid raw values mean the INA226 is offline or a read failed.";
CM_ BO_ 1441 "Low-voltage battery branch status. Positive current means battery discharge/load consumption; negative means charging. Signed convention validated by serial load test. Energy is accumulated since MCU boot and is not battery state of charge.";
CM_ BO_ 1442 "Three fan speeds and two measured fan-side PWM duty cycles. 100ms cycle.";
CM_ BO_ 1443 "Fan faults, input validity, control mode, maximum temperatures and target duty cycles. 500ms cycle. MaxMotorTemp/MaxControllerTemp are 0x7FFF (big-endian int16) when the corresponding source is stale or unavailable; do not treat that as -0.1 C.";
CM_ BO_ 1444 "V4: 01 control; 04 defaults; 05 query; 08 calibration (P1=1 start/2 update/3 stop, P2=step, P3/P4=PWM1/PWM2 0..100%, P5=lease 1..60s; stop P3..5=0). Calibration actions 4/5/6 and opcodes 02/03/06 unsupported. 09 profile; 0A clear stall locks. Byte0 opcode, Byte1 sequence, Byte2..6 params, Byte7 CRC8 SAE-J1850 over bytes0..6.";
CM_ BO_ 1445 "Fan command acknowledgement and current control state. AckResult 7 means Flash write or read-back failed; Session remains COMPLETED so COMMIT can be retried.";
CM_ BO_ 1448 "Fan power arbitration status, including power supply state, limits, independent thermal requests, targets and predicted current. 100ms cycle.";
CM_ BO_ 1449 "V4 calibration status, 500ms and command events, including idle. Uint Intel, scale1 offset0. ParamVersion=4 identifies calibration support; age>1500ms invalid. Flags bit0=output paused until explicit UPDATE. Legacy V3 layout preserved; no Flash cap commit.";
CM_ BO_ 513 "CANB 标准帧 0x201；Byte3..6 为小端 IEEE-754 float 电压，BMS 接收时要求 DLC 至少为 7。";
CM_ BO_ 514 "CANB 标准帧 0x202；Byte3..6 为小端 IEEE-754 float 电流，BMS 接收时要求 DLC 至少为 7。";
CM_ BO_ 516 "CANB 标准帧 0x204；Byte3..6 为小端 uint32，0 表示没有保护状态，BMS 接收时要求 DLC 至少为 7。";
CM_ BO_ 517 "CANB 标准帧 0x205；Byte3 为输出状态，0 表示关闭，BMS 接收时要求 DLC 至少为 4。";
CM_ BO_ 656 "CANB 标准帧 0x290；DLC=3 的字节命令或 DLC=6 的 float/uint32 命令，参数从 Byte2 开始并使用小端；BMS 当前将四类反馈周期设为 500 ms。";
CM_ BO_ 657 "CANB 标准帧 0x291；成功时 Byte0 为命令码加 0x40，失败时 Byte0=0x7F、Byte1 为失败命令码。";
CM_ BO_ 1184 "CANB 标准帧 0x4A0，放电模式高压接通后 10 ms；四个上限均为小端无符号值。";
CM_ BO_ 1187 "CANB 标准帧 0x4A3，紧跟 0x4A0；Byte7 为跨 0x4A0/0x4A3 的 CRC-8/SAE-J1850。";
CM_ BO_ 1188 "CANB 标准帧 0x4A4；ECU 确认采用的 SOP 组，Byte7 为 CRC-8/SAE-J1850。";
CM_ BO_ 1200 "CANB 标准帧 0x4B0，500 ms；电压、电流和 SOC 必须结合 Byte5 有效位使用。";
CM_ BO_ 1201 "CANB 标准帧 0x4B1，500 ms，并在状态变化时补发；当前格式版本为 4，fault bit22 保留。版本3的bit22是旧版外部安回事件。";
CM_ BO_ 1202 "CANB 标准帧 0x4B2，500 ms，并在告警变化时补发；0 未触发，1 一级故障，2 二级告警，3 保留。";
CM_ BO_ 1072 "FS Datalogger 赛会能量计状态帧；Byte2..3 为大端电压 raw*16 mV，Byte4..5 为大端电流 raw*64 mA。";
CM_ BO_ 1313 "赛会能量计电流结果，标准帧 0x521；MUX=0x00，Byte2..5 为大端有符号 int32 mA。";
CM_ BO_ 1314 "赛会能量计 U1 逆变器侧总压，标准帧 0x522；MUX=0x01，Byte2..5 为大端有符号 int32 mV。";
CM_ BO_ 1318 "赛会能量计功率结果，标准帧 0x526；MUX=0x05，Byte2..5 为大端有符号 int32 W；设备可能不发送。";
CM_ BO_ 1320 "赛会能量计 Wh 结果，标准帧 0x528；MUX=0x07，Byte2..5 为大端有符号 int32 Wh；设备可能不发送。";
CM_ BO_ 2550588916 "CANB 扩展帧 0x1806E5F4，Legacy 充电模式约 1 s；Byte4=1 表示停止。";
CM_ BO_ 2566869221 "CANB 扩展帧 0x18FF50E5；BMS 接收时要求 DLC 至少为 5，Byte5..7 不参与当前接口。";
CM_ BO_ 1450 "Battery-box fan status. Sent continuously from power-on: 100 ms in discharge HV_ON with no Chroma stop request, active command or bench session; 200 ms in Chroma charge/precharge or standby manual/calibration session; 500 ms otherwise. On a period change wait from the last successful send; while Chroma is present on CANB consecutive frames of this ID must be at least 150 ms apart. At least 5% duty is required before a stall is confirmed (5 s no RPM, clear after 2 s RPM); the status flag indicates at least a 5% target was active.";
CM_ BO_ 1451 "Battery-box fan control, query and power-calibration command. Byte7 is CRC-8 SAE-J1850 over bytes 0..6. Opcode 0x01 SetControl, 0x02 legacy Query (acknowledged without changing report periods), 0x03 CalibrationSession, 0x04 CommitPowerLimits, 0x05 ClearCalibration. Manual/Off and calibration lease time must be 1..60 s; SetControl Auto requires all parameters zero; Off requires duty zero.";
CM_ BO_ 1452 "Event acknowledgement for 0x5AB. Match both opcode and request counter. Result 7 means external Flash is unavailable; result 6 means a safety condition rejected the command.";
CM_ BO_ 1453 "Battery-box fan 35 W/70 W caps, Flash-save state and calibration-session status. Sent continuously every 500 ms in all states. Bit1=1 means Flash save is pending or retrying; clear before power-off and verify after a full reset. Valid caps must satisfy 5 <= Chroma <= HV <= 100; otherwise boot restores 55/55.";
CM_ BO_ 1454 "Historical V3 frame. V4 does not transmit; use 0x5AF for profile and per-channel caps.";
CM_ BO_ 1455 "V4 fixed profile status, 500ms. All fields unsigned Intel, scale1 offset0. No in-frame invalid sentinel; receiver treats age>1500ms as invalid. Version must be4.";
CM_ BO_ 774 "Gateway forward of CANC 0x270 IBS_Info brake pedal signals (WCBS source, 20ms cycle). BrakePedalPct mirrors AB_BrkPdlPct rescaled to 0.1%/LSB matching 0x305 APS_OpenPct layout; BrakePedalSwtSts mirrors AB_BrkPdlSwtSts.";
CM_ SG_ 774 BrakePedalSwtSts "Brake pedal switch status, mirrors CANC AB_BrkPdlSwtSts";
CM_ SG_ 774 BrakePedalPct "Brake pedal percent 0..100%, 0.1%/LSB";
BA_DEF_ SG_  "SystemSignalLongSymbol" STRING ;
BA_DEF_ BO_  "GenMsgCycleTime" INT 0 65535;
BA_DEF_DEF_  "SystemSignalLongSymbol" "";
BA_DEF_DEF_  "GenMsgCycleTime" 0;
BA_ "GenMsgCycleTime" BO_ 1440 100;
BA_ "GenMsgCycleTime" BO_ 1441 100;
BA_ "GenMsgCycleTime" BO_ 1442 100;
BA_ "GenMsgCycleTime" BO_ 1443 500;
BA_ "GenMsgCycleTime" BO_ 1448 100;
BA_ "GenMsgCycleTime" BO_ 1449 500;
BA_ "SystemSignalLongSymbol" SG_ 1202 DischargeSustainedOvercurrentLev "DischargeSustainedOvercurrentLevel";
BA_ "GenMsgCycleTime" BO_ 1450 100;
BA_ "GenMsgCycleTime" BO_ 1453 500;
BA_ "GenMsgCycleTime" BO_ 1454 500;
BA_ "GenMsgCycleTime" BO_ 1455 500;
BA_ "GenMsgCycleTime" BO_ 774 20;
VAL_ 1444 CommandOpcode 1 "SetControl" 2 "SetCurveCH1" 3 "SetFailsafe" 4 "RestoreDefaults" 5 "Query" 6 "SetCurveCH2" 8 "SetCalib" 9 "SetProfile" 10 "ClearFaults" ;
VAL_ 1445 AckFailsafe 0 "HoldLast" 1 "Fallback" 2 "Full" ;
VAL_ 1445 AckMode 0 "Auto" 1 "Manual" 2 "Off" ;
VAL_ 1445 AckResult 0 "OK" 1 "BadCRC" 2 "BadLength" 3 "BadValue" 4 "Unsupported" 5 "LeaseExpired" 6 "SafetyAbort" 7 "StorageError" ;
VAL_ 1447 FanControlMode 0 "Auto" 1 "Manual" 2 "Off" ;
VAL_ 1447 FanFailsafeStrategy 0 "HoldLast" 1 "Fallback" 2 "Full" ;
VAL_ 1448 PowerLimitReason 0 "None" 1 "BusLimit" 2 "BatteryLimit" 3 "PdmTimeout" 4 "TransitionHold" 5 "StallHold" 6 "OverTemperature" 7 "SafetyAbort" 8 "LowVoltage" ;
VAL_ 1448 PowerSupplyState 0 "Unknown" 1 "Battery" 2 "Transition" 3 "DcdcReady" 4 "PowerLimited" 5 "DataFault" ;
VAL_ 1449 CalibAbortReason 0 "None" 1 "SupplyStateChanged" 2 "PdmTimeout" 3 "PowerLimit" 4 "OverTemp" 5 "FanStall" 6 "LeaseExpired" 7 "UserStop" ;
VAL_ 1449 CalibState 0 "Inactive" 1 "Active" 2 "Aborted" 3 "Completed" ;
VAL_ 1187 InterventionLevel 0 "Normal" 1 "Derating" 2 "OvercurrentZero" 3 "FaultOrShutdown" ;
VAL_ 1200 BatteryState 2 "SelfTest" 3 "Standby" 4 "Precharge" 5 "HighVoltageOn" 7 "FaultHold" ;
VAL_ 1200 BatteryAlarmLevel 0 "Normal" 1 "Level1Fault" 2 "Level2Alarm" ;
VAL_ 1450 BatteryFanPowerSource 0 "LowVoltageOrDisabled" 1 "Chroma35W" 2 "VehicleHvDcdc70W" ;
VAL_ 1450 BatteryFanMode 0 "Auto" 1 "Manual" 2 "Off" ;
VAL_ 1451 BatteryFanCommandOpcode 1 "SetControl" 2 "Query" 3 "CalibrationSession" 4 "CommitPowerLimits" 5 "ClearCalibration" ;
VAL_ 1452 BatteryFanAckPowerSource 0 "LowVoltageOrDisabled" 1 "Chroma35W" 2 "VehicleHvDcdc70W" ;
VAL_ 1452 BatteryFanAckMode 0 "Auto" 1 "Manual" 2 "Off" ;
VAL_ 1452 BatteryFanAckResult 0 "OK" 1 "BadCRC" 2 "BadLength" 3 "BadValue" 4 "Unsupported" 5 "LeaseExpired" 6 "SafetyAbort" 7 "StorageUnavailable" ;
VAL_ 1453 BatteryFanCalibrationAbortReason 0 "None" 1 "StateChanged" 2 "OverTemperature" 3 "FanStall" 4 "LeaseExpired" 5 "UserStop" 6 "PwmOrTachStartFailure" ;
VAL_ 1453 BatteryFanCalibrationState 0 "Inactive" 1 "Active" 2 "Aborted" 3 "Completed" ;
VAL_ 1454 ActivePowerTier 0 "Battery" 1 "Dcdc" ;
VAL_ 1455 LimitReason 0 "None" 1 "BusLimit" 2 "BatteryLimit" 3 "PdmTimeout" 4 "TransitionHold" 5 "StallHold" 6 "OverTemperature" 7 "SafetyAbort" 8 "LowVoltage" ;
VAL_ 1455 SourceState 0 "Unknown" 1 "Battery" 2 "Transition" 3 "DcdcReady" 4 "Limited" 5 "DataFault" ;
VAL_ 1455 EffectiveStrategy2 0 "Conservative" 1 "Default" 2 "Aggressive" 3 "Battery" 4 "StaleHold" 5 "Fallback" 6 "Stopped" 7 "Critical" 8 "Manual" 9 "Calibration" ;
VAL_ 1455 EffectiveStrategy1 0 "Conservative" 1 "Default" 2 "Aggressive" 3 "Battery" 4 "StaleHold" 5 "Fallback" 6 "Stopped" 7 "Critical" 8 "Manual" 9 "Calibration" ;
VAL_ 1455 RequestedProfile 0 "Conservative" 1 "Default" 2 "Aggressive" ;
VAL_ 774 BrakePedalSwtSts 0 "unpressed" 1 "pressed" ;
SIG_VALTYPE_ 513 ChromaVoltage : 1;
SIG_VALTYPE_ 514 ChromaCurrent : 1;
